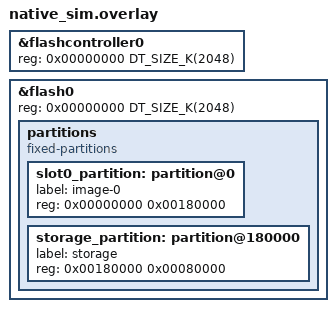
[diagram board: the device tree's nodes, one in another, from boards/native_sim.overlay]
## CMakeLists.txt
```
# SPDX-License-Identifier: GPL-3.0-or-later
#
# Method 5 (PAIRING_CA_ANCHOR_PLUS_PASSKEY) pairing gate conformance on native_sim (T-20).
#
# Drives pairing.c (CA_ANCHOR_PLUS_PASSKEY path) + ca.c + storage.c against a
# simulated LittleFS partition.  Suite setup provisions slot 0 as a CA (the
# trust anchor) and generates a test client cert signed by it.
#
# Build:
#   ZEPHYR_TOOLCHAIN_VARIANT=host \
#     west build -p -b native_sim firmware/tests/pairing_ca_anchor_passkey --no-sysbuild
#   west build -t run

cmake_minimum_required(VERSION 3.20.0)

find_package(Zephyr REQUIRED HINTS $ENV{ZEPHYR_BASE})
project(pairing_ca_anchor_passkey_tests LANGUAGES C)

set(FW ${CMAKE_CURRENT_SOURCE_DIR}/../..)

target_sources(app PRIVATE
    src/main.c
    src/session_stub.c
    src/gesture_stub.c
    src/led_stub.c
    ${FW}/src/clients/pairing.c
    ${FW}/src/clients/client_bond.c
    ${FW}/src/ca/ca.c
    ${FW}/src/ca/der_write.c
    ${FW}/src/ca/certparse_wolfssl.c
    ${FW}/src/ca/certgen_wolfssl.c
    ${FW}/src/crypto/crypto_wolfssl.c
    ${FW}/src/crypto/wc_rand.c
    ${FW}/src/crypto/zeroize.c
    ${FW}/src/storage/storage.c
    ${FW}/src/storage/volume_marker.c
    ${FW}/src/crypto/device_id.c
    ${FW}/../common/cbor/cantil_cbor.c
)

target_include_directories(app PRIVATE
    ${FW}/src
    ${FW}/include
    ${FW}/../common/cbor
    ${FW}/tests/common
)

zephyr_include_directories(${FW}/include)

# Carries WOLFSSL_USER_SETTINGS / WOLFSSL_ZEPHYR defines.
target_link_libraries(app PRIVATE wolfSSL)
```

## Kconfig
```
# SPDX-License-Identifier: GPL-3.0-or-later

mainmenu "pairing_ca_anchor_passkey ztest"

config CANTIL_MAX_KEY_SLOTS
	int "Maximum number of key slots"
	default 8
	range 1 64

config CANTIL_MAX_CLIENT_BONDS
	int "Maximum number of host-client bonds"
	default 2
	range 1 16

config CANTIL_MAX_PEER_BONDS
	int "Maximum number of peer-device bonds"
	default 2
	range 1 8

config CANTIL_CRL_VALIDITY_SEC
	int "CRL nextUpdate window (seconds)"
	default 86400

config CANTIL_REVOKE_REQUIRE_NOW_UNIX
	bool "Require host-supplied revocation timestamp"
	default n

# Pairing method symbols — flat booleans (no choice wrapper in test context).
config PAIRING_PROMISCUOUS
	bool "Method 0 — Promiscuous"
	default n

config PAIRING_TOFU
	bool "Method 1 — Silent TOFU"
	default n

config PAIRING_TAP_CONFIRM
	bool "Method 2 — Tap-confirmed bond"
	default n

config PAIRING_PASSKEY
	bool "Method 3 — Passkey + tap-confirmed bond"
	default n

config PAIRING_CA_ANCHOR
	bool "Method 4 — CA-anchored client cert"
	default n

config PAIRING_CA_ANCHOR_PLUS_PASSKEY
	bool "Method 5 — CA-anchored + passkey"
	default n

config CANTIL_CA_ANCHOR_SLOT
	int "CA slot to use as trust anchor for Method 4/5"
	default 0
	depends on PAIRING_CA_ANCHOR || PAIRING_CA_ANCHOR_PLUS_PASSKEY

config CANTIL_PAIR_TIMEOUT_SEC
	int "Pairing prompt timeout (seconds)"
	default 30

config CANTIL_PASSKEY_TIMEOUT_SEC
	int "Passkey entry timeout (seconds)"
	default 60
	depends on PAIRING_PASSKEY || PAIRING_CA_ANCHOR_PLUS_PASSKEY

config CANTIL_PASSKEY_BLINK_PAUSE_MS
	int "Inter-digit pause during passkey LED blink (milliseconds)"
	default 0
	depends on PAIRING_PASSKEY || PAIRING_CA_ANCHOR_PLUS_PASSKEY

source "Kconfig.zephyr"
```

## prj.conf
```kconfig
# ztest framework
CONFIG_ZTEST=y

# Pairing method under test.
CONFIG_PAIRING_CA_ANCHOR_PLUS_PASSKEY=y
CONFIG_CANTIL_CA_ANCHOR_SLOT=0
CONFIG_CANTIL_PAIR_TIMEOUT_SEC=30
CONFIG_CANTIL_PASSKEY_TIMEOUT_SEC=60
CONFIG_CANTIL_PASSKEY_BLINK_PAUSE_MS=0

CONFIG_CANTIL_MAX_CLIENT_BONDS=2
CONFIG_CANTIL_MAX_PEER_BONDS=2

# Entropy — native_sim has zephyr,native-posix-rng.
CONFIG_ENTROPY_GENERATOR=y
CONFIG_TEST_RANDOM_GENERATOR=y

# LittleFS on the sim flash partition.
CONFIG_FLASH=y
CONFIG_FLASH_MAP=y
CONFIG_FILE_SYSTEM=y
CONFIG_FILE_SYSTEM_LITTLEFS=y
CONFIG_FS_LITTLEFS_FMP_DEV=y
CONFIG_FILE_SYSTEM_MKFS=y

# wolfCrypt — full CA path (ECDSA P-256, AES-256-GCM, HKDF-SHA256) plus the
# X.509 writer and reader. Which primitives compile is decided by the settings
# header, not by Kconfig — see cantil_wolfssl_user_settings.h.
CONFIG_WOLFSSL=y
CONFIG_WOLFSSL_BUILTIN=y
CONFIG_WOLFSSL_SETTINGS_FILE="cantil_wolfssl_user_settings.h"

# Device-id source for the FICR-derived storage key.
CONFIG_HWINFO=y

CONFIG_MAIN_STACK_SIZE=16384
CONFIG_HEAP_MEM_POOL_SIZE=32768

# crc32_ieee — storage.c volume identity marker
CONFIG_CRC=y
```

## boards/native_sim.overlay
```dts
/* Same flash layout as other pairing tests — 512 KB storage partition. */

&flashcontroller0 {
	reg = <0x00000000 DT_SIZE_K(2048)>;
};

&flash0 {
	reg = <0x00000000 DT_SIZE_K(2048)>;
	partitions {
		compatible = "fixed-partitions";
		#address-cells = <1>;
		#size-cells = <1>;

		/delete-node/ partition@0;
		/delete-node/ partition@c000;
		/delete-node/ partition@75000;
		/delete-node/ partition@de000;
		/delete-node/ partition@fc000;

		slot0_partition: partition@0 {
			label = "image-0";
			reg = <0x00000000 0x00180000>;
		};
		storage_partition: partition@180000 {
			label = "storage";
			reg = <0x00180000 0x00080000>;
		};
	};
};
```

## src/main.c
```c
/* SPDX-License-Identifier: GPL-3.0-or-later */
/* See LICENSE at the repo root. */

/*
 * Method 5 (PAIRING_CA_ANCHOR_PLUS_PASSKEY) pairing gate conformance on
 * native_sim (T-20).
 *
 * Drives pairing.c + ca.c + storage.c against a simulated flash partition.
 * Suite setup provisions slot 0 as a CA (the trust anchor) and generates a
 * test client cert signed by it.  Per-test setup resets all stub state.
 *
 * Method 5 = cert chain validation (Method 4) + passkey + tap-confirm (Method 3).
 * A known (previously-bonded) client skips both gates.
 *
 * Coverage:
 *   1. Valid cert + correct passkey + gesture OK → bonded + PSK stored.
 *   2. No client cert in msg3 → -EACCES (cert gate rejects before passkey).
 *   3. Cert from wrong CA (self-signed) → -EACCES (cert gate).
 *   4. Valid cert + wrong passkey → -EACCES + ERR_AUTH, not bonded.
 *   5. Valid cert + transport timeout → -EACCES, not bonded.
 *   6. Valid cert + correct passkey + gesture denied → -EACCES, not bonded.
 *   7. Already-bonded client (known) → allowed with no cert or passkey.
 *   8. Valid cert + cap full → -EACCES without passkey prompt.
 */

#include <zephyr/kernel.h>
#include <zephyr/ztest.h>
#include <zephyr/fs/fs.h>
#include <string.h>
#include <errno.h>

#include "ca/ca.h"
#include "test_pki.h"
#include "crypto/crypto.h"
#include "storage/storage.h"
#include "clients/pairing.h"
#include "clients/client_bond.h"
#include "gesture/gesture.h"
#include "session/session.h"
#include "protocol/protocol.h"

/* Declared in session_stub.c */
cantil_session_t *m5_test_session(void);
void m5_test_set_client_certs(const uint8_t *const ders[], const size_t lens[], size_t count);
void m5_test_clear_client_certs(void);
void m5_test_set_reply_digits(uint32_t digits);
void m5_test_lock_digits(uint32_t digits);
void m5_test_set_reply_timeout(void);
uint32_t m5_test_last_response_err(void);
void m5_test_reset(void);

/* Declared in gesture_stub.c */
void m5_test_set_gesture_result(cantil_confirm_result_t r);

/* ── Test-owned cert DER buffers (populated once in suite_setup) ─────────── */

static uint8_t g_anchor_cert_der[1024];
static size_t g_anchor_cert_len;

static uint8_t g_valid_cert_der[1024]; /* client cert signed by slot 0 */
static size_t g_valid_cert_len;

static uint8_t g_self_signed_cert_der[1024]; /* cert with unknown CA */
static size_t g_self_signed_cert_len;

/* ── Helpers ─────────────────────────────────────────────────────────────── */

static void wipe_dir(const char *path)
{
	struct fs_dir_t dir;
	struct fs_dirent ent;
	char child[128];

	fs_dir_t_init(&dir);
	if (fs_opendir(&dir, path) != 0) {
		return;
	}
	while (fs_readdir(&dir, &ent) == 0 && ent.name[0] != '\0') {
		snprintf(child, sizeof(child), "%s/%s", path, ent.name);
		if (ent.type == FS_DIR_ENTRY_DIR) {
			wipe_dir(child);
		}
		fs_unlink(child);
	}
	fs_closedir(&dir);
	fs_unlink(path);
}

static size_t build_ca_x509_blob(uint8_t *out, size_t cap)
{
	size_t off = 0;
	const char *cn = "Cantil Test CA";
	const char *o = "Cantil";

	zassert_true(cap >= 64, "blob buffer too small");
	out[off++] = 0x01;
	out[off++] = 0x68; /* validity_days = 360 */
	out[off++] = 1;    /* is_ca */
	out[off++] = 0;    /* path_len = 0 */
	out[off++] = 0x00;
	out[off++] = 0x86; /* KU: digSig|keyCertSign|cRLSign */

	out[off++] = (uint8_t)strlen(cn);
	memcpy(&out[off], cn, strlen(cn));
	off += strlen(cn);
	out[off++] = (uint8_t)strlen(o);
	memcpy(&out[off], o, strlen(o));
	off += strlen(o);
	out[off++] = 0; /* ou */
	out[off++] = 0; /* c  */
	out[off++] = 0; /* st */
	out[off++] = 0; /* l  */
	return off;
}

/* A fresh client CSR (CN=TestClient), minted via the wolfCrypt writer. */
static int build_client_csr(uint8_t *csr_der, size_t *csr_len)
{
	return test_pki_csr_cn("TestClient", csr_der, csr_len, NULL);
}

/* A self-signed leaf under an unrelated key (CN=Unknown) — a cert that does
 * NOT chain to slot 0, which the trust-tier tests expect to be rejected. */
static int build_self_signed_cert(uint8_t *cert_der, size_t *cert_len)
{
	certgen_dn_t dn = test_pki_dn_cn("Unknown");

	return test_pki_self_signed(&dn, false, cert_der, cert_len, NULL);
}

/* ── Passkey hook ────────────────────────────────────────────────────────── */

void pairing_test_passkey_hook(uint32_t passkey)
{
	m5_test_set_reply_digits(passkey);
}

/* ── Suite setup ─────────────────────────────────────────────────────────── */

static void *suite_setup(void)
{
	zassert_ok(storage_init(), "storage_init failed");

	/*
	 * A fresh native_sim volume has no identity marker, and minting is now
	 * refused on an unmarked, empty volume — that combination is what a
	 * misdeclared partition looks like. Mark it, which is exactly what the
	 * factory image does to real hardware before anything is provisioned.
	 */
	(void)storage_volume_marker_write();

	wipe_dir("/lfs/keys/0");
	zassert_ok(ca_provision(0), "ca_provision failed");

	uint8_t blob[64];
	size_t blob_len = build_ca_x509_blob(blob, sizeof(blob));

	zassert_ok(ca_push_key_x509(0, blob, blob_len), "ca_push_key_x509 failed");
	zassert_true(ca_ready(), "slot 0 not ready after push");

	g_anchor_cert_len = sizeof(g_anchor_cert_der);
	zassert_ok(storage_slot_cert_read(0, g_anchor_cert_der, &g_anchor_cert_len),
		   "could not read slot 0 cert after push");

	/* Sign a test client CSR with slot 0 → g_valid_cert_der. */
	uint8_t csr_buf[512];
	size_t csr_len = sizeof(csr_buf);

	zassert_ok(build_client_csr(csr_buf, &csr_len), "client CSR build failed");

	g_valid_cert_len = sizeof(g_valid_cert_der);
	zassert_ok(ca_sign_csr_slot(0, csr_buf, csr_len, g_valid_cert_der, &g_valid_cert_len),
		   "CA sign CSR failed");

	/* Build a self-signed cert not anchored in slot 0 → g_self_signed_cert_der. */
	g_self_signed_cert_len = sizeof(g_self_signed_cert_der);
	zassert_ok(build_self_signed_cert(g_self_signed_cert_der, &g_self_signed_cert_len),
		   "self-signed cert build failed");

	return NULL;
}

static void before(void *unused)
{
	ARG_UNUSED(unused);
	wipe_dir("/lfs/clients");
	m5_test_reset();
	m5_test_set_gesture_result(CANTIL_CONFIRM_OK);
}

ZTEST_SUITE(pairing_ca_anchor_passkey, NULL, suite_setup, before, NULL, NULL);

static const uint8_t PUB_A[32] = {0xAA, 0x01, 0x02, 0x03, 0, 0, 0, 0, 0, 0, 0, 0, 0, 0, 0, 0,
				  0,    0,    0,    0,    0, 0, 0, 0, 0, 0, 0, 0, 0, 0, 0, 0};
static const uint8_t PUB_B[32] = {0xBB, 0x01, 0x02, 0x03, 0, 0, 0, 0, 0, 0, 0, 0, 0, 0, 0, 0,
				  0,    0,    0,    0,    0, 0, 0, 0, 0, 0, 0, 0, 0, 0, 0, 0};
static const uint8_t PUB_C[32] = {0xCC, 0x01, 0x02, 0x03, 0, 0, 0, 0, 0, 0, 0, 0, 0, 0, 0, 0,
				  0,    0,    0,    0,    0, 0, 0, 0, 0, 0, 0, 0, 0, 0, 0, 0};

/* ── Test 1: valid cert + correct passkey + gesture OK → bonded + PSK ───── */

ZTEST(pairing_ca_anchor_passkey, test_valid_cert_passkey_bonded)
{
	const uint8_t *ders[1] = {g_valid_cert_der};
	size_t lens[1] = {g_valid_cert_len};

	m5_test_set_client_certs(ders, lens, 1);

	cantil_session_t *s = m5_test_session();

	zassert_ok(pairing_check_and_bond(PUB_A, s),
		   "Method 5: valid cert + passkey should be allowed");

	zassert_equal(client_bond_exists(PUB_A), 1, "bond not stored after Method 5 success");

	/* PSK file must exist and be non-empty. */
	uint8_t id[4] = {0xAA, 0x01, 0x02, 0x03};
	uint8_t psk_enc[64];
	size_t psk_enc_len = sizeof(psk_enc);

	zassert_ok(storage_client_bond_psk_read(id, psk_enc, &psk_enc_len),
		   "PSK not stored after Method 5");
	zassert_true(psk_enc_len > 0, "PSK blob is empty");

	zassert_equal(m5_test_last_response_err(), (uint32_t)ERR_OK,
		      "device sent non-OK response on success");
}

/* ── Test 2: no cert in msg3 → rejected before passkey ──────────────────── */

ZTEST(pairing_ca_anchor_passkey, test_no_cert_rejected)
{
	/* No certs injected — stub returns cert_count == 0. */
	m5_test_set_reply_timeout(); /* recv would error if called */

	cantil_session_t *s = m5_test_session();
	int rc = pairing_check_and_bond(PUB_A, s);

	zassert_equal(rc, -EACCES, "Method 5: no cert should be rejected, got %d", rc);
	zassert_equal(client_bond_exists(PUB_A), 0, "bonded despite missing cert");
}

/* ── Test 3: self-signed cert (wrong CA) → rejected before passkey ───────── */

ZTEST(pairing_ca_anchor_passkey, test_wrong_ca_rejected)
{
	const uint8_t *ders[1] = {g_self_signed_cert_der};
	size_t lens[1] = {g_self_signed_cert_len};

	m5_test_set_client_certs(ders, lens, 1);
	m5_test_set_reply_timeout(); /* recv would error if called */

	cantil_session_t *s = m5_test_session();
	int rc = pairing_check_and_bond(PUB_A, s);

	zassert_equal(rc, -EACCES, "Method 5: cert from wrong CA should be rejected, got %d", rc);
	zassert_equal(client_bond_exists(PUB_A), 0, "bonded despite invalid cert");
}

/* ── Test 4: valid cert + wrong passkey → -EACCES + ERR_AUTH ────────────── */

ZTEST(pairing_ca_anchor_passkey, test_wrong_passkey_rejected)
{
	const uint8_t *ders[1] = {g_valid_cert_der};
	size_t lens[1] = {g_valid_cert_len};

	m5_test_set_client_certs(ders, lens, 1);
	/* Lock stub to 0 — generate_passkey() never returns 0, so always a mismatch. */
	m5_test_lock_digits(0U);

	cantil_session_t *s = m5_test_session();
	int rc = pairing_check_and_bond(PUB_A, s);

	zassert_equal(rc, -EACCES, "Method 5: wrong passkey should reject, got %d", rc);
	zassert_equal(client_bond_exists(PUB_A), 0, "bonded despite wrong passkey");
	zassert_equal(m5_test_last_response_err(), (uint32_t)ERR_AUTH,
		      "expected ERR_AUTH response, got %u", m5_test_last_response_err());
}

/* ── Test 5: valid cert + passkey recv timeout → -EACCES ─────────────────── */

ZTEST(pairing_ca_anchor_passkey, test_timeout_rejected)
{
	const uint8_t *ders[1] = {g_valid_cert_der};
	size_t lens[1] = {g_valid_cert_len};

	m5_test_set_client_certs(ders, lens, 1);
	m5_test_set_reply_timeout();

	cantil_session_t *s = m5_test_session();
	int rc = pairing_check_and_bond(PUB_A, s);

	zassert_equal(rc, -EACCES, "Method 5: passkey timeout should reject, got %d", rc);
	zassert_equal(client_bond_exists(PUB_A), 0, "bonded despite timeout");
}

/* ── Test 6: valid cert + correct passkey + gesture denied → -EACCES ──────── */

ZTEST(pairing_ca_anchor_passkey, test_gesture_denied_rejected)
{
	const uint8_t *ders[1] = {g_valid_cert_der};
	size_t lens[1] = {g_valid_cert_len};

	m5_test_set_client_certs(ders, lens, 1);
	m5_test_set_gesture_result(CANTIL_CONFIRM_DENIED);

	cantil_session_t *s = m5_test_session();
	int rc = pairing_check_and_bond(PUB_A, s);

	zassert_equal(rc, -EACCES, "Method 5: denied gesture should reject, got %d", rc);
	zassert_equal(client_bond_exists(PUB_A), 0, "bonded despite denied gesture");
}

/* ── Test 7: already-bonded client → allowed with no cert or passkey ─────── */

ZTEST(pairing_ca_anchor_passkey, test_known_client_allowed)
{
	/* Pre-establish a bond for PUB_A. */
	zassert_ok(client_bond_add(PUB_A, CLIENT_KIND_HOST, 0), "setup bond");

	/* No cert injected, recv would timeout if called. */
	m5_test_set_reply_timeout();

	cantil_session_t *s = m5_test_session();

	zassert_ok(pairing_check_and_bond(PUB_A, s), "Method 5: known client should be allowed");

	uint32_t hosts = 0, peers = 0;

	zassert_ok(client_bond_count(&hosts, &peers), "count failed");
	zassert_equal(hosts, 1, "expected 1 bond, got %u", hosts);
}

/* ── Test 8: valid cert + cap full → -EACCES without passkey prompt ─────── */

ZTEST(pairing_ca_anchor_passkey, test_cap_full_rejected)
{
	/* Fill the cap (max 2 per prj.conf). */
	zassert_ok(client_bond_add(PUB_A, CLIENT_KIND_HOST, 0), "bond A");
	zassert_ok(client_bond_add(PUB_B, CLIENT_KIND_HOST, 0), "bond B");

	const uint8_t *ders[1] = {g_valid_cert_der};
	size_t lens[1] = {g_valid_cert_len};

	m5_test_set_client_certs(ders, lens, 1);
	m5_test_set_reply_timeout(); /* recv must not be called */

	cantil_session_t *s = m5_test_session();
	int rc = pairing_check_and_bond(PUB_C, s);

	zassert_equal(rc, -EACCES, "Method 5: cap full should reject, got %d", rc);
	zassert_equal(client_bond_exists(PUB_C), 0, "bonded despite cap full");
}
```

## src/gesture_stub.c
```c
/* SPDX-License-Identifier: GPL-3.0-or-later */
/* See LICENSE at the repo root. */

#include "gesture/gesture.h"

static cantil_confirm_result_t stub_result = CANTIL_CONFIRM_OK;

void m5_test_set_gesture_result(cantil_confirm_result_t r)
{
	stub_result = r;
}

int gesture_request_pair_confirm(cantil_confirm_cb_t cb, void *user_data)
{
	cb(stub_result, user_data);
	return 0;
}
```

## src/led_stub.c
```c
/* SPDX-License-Identifier: GPL-3.0-or-later */
/* See LICENSE at the repo root. */

#include <zephyr/kernel.h>
#include "led/led.h"

int led_init(void)
{
	return 0;
}

void led_set_idle(led_pattern_t pattern)
{
	ARG_UNUSED(pattern);
}
void led_play_oneshot(led_pattern_t pattern)
{
	ARG_UNUSED(pattern);
}
void led_set_pattern(led_pattern_t pattern)
{
	ARG_UNUSED(pattern);
}

void led_blink_digit(uint8_t digit)
{
	ARG_UNUSED(digit);
}

void led_diag_flash(uint8_t color, uint32_t ms)
{
	ARG_UNUSED(color);
	ARG_UNUSED(ms);
}
```

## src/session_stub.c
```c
/* SPDX-License-Identifier: GPL-3.0-or-later */
/* See LICENSE at the repo root. */

/*
 * Session stub for the pairing_ca_anchor_passkey ztest suite (T-20).
 *
 * pairing.c (PAIRING_CA_ANCHOR_PLUS_PASSKEY) calls:
 *   session_get_client_cert_count() — how many client certs the peer sent
 *   session_get_client_cert()       — borrow the Nth cert DER
 *   session_recv()                  — receive CMD_PAIRING_PASSKEY_REPLY
 *   session_send()                  — send the pairing response
 *   session_get_local_pubkey()      — device static pubkey for PSK derivation
 *
 * Test controls:
 *   m5_test_session()                — return the stub cantil_session_t *
 *   m5_test_set_client_certs()       — inject client cert chain
 *   m5_test_clear_client_certs()     — reset to "no cert" (cert_count == 0)
 *   m5_test_set_reply_digits(d)      — session_recv returns CBOR{cmd=0x73, data=d}
 *   m5_test_lock_digits(d)           — same, but ignores hook overrides
 *   m5_test_set_reply_timeout()      — session_recv returns -ETIMEDOUT
 *   m5_test_last_response_err()      — last err value from session_send
 *   m5_test_reset()                  — clear all passkey/recv state
 */

#include <zephyr/kernel.h>
#include <string.h>
#include <errno.h>

#include "session/session.h"
#include "cantil_cbor.h"
#include "protocol/protocol.h"

#define MAX_TEST_CERTS 4

struct cantil_session {
	bool established;
	/* Injected client cert chain (borrowed pointers). */
	const uint8_t *cert_ders[MAX_TEST_CERTS];
	size_t cert_lens[MAX_TEST_CERTS];
	size_t cert_count;
};

static struct cantil_session stub_session = {.established = true};

cantil_session_t *m5_test_session(void)
{
	return &stub_session;
}

/* ── Cert injection controls ─────────────────────────────────────────────── */

void m5_test_set_client_certs(const uint8_t *const ders[], const size_t lens[], size_t count)
{
	stub_session.cert_count = (count > MAX_TEST_CERTS) ? MAX_TEST_CERTS : count;
	for (size_t i = 0; i < stub_session.cert_count; i++) {
		stub_session.cert_ders[i] = ders[i];
		stub_session.cert_lens[i] = lens[i];
	}
}

void m5_test_clear_client_certs(void)
{
	stub_session.cert_count = 0;
}

/* ── Passkey reply controls ──────────────────────────────────────────────── */

static uint32_t stub_digits = 0;
static bool stub_digits_locked = false;
static bool stub_timeout = false;
static uint32_t stub_last_err = UINT32_MAX;

void m5_test_set_reply_digits(uint32_t digits)
{
	if (!stub_digits_locked) {
		stub_digits = digits;
	}
}

void m5_test_lock_digits(uint32_t digits)
{
	stub_digits = digits;
	stub_digits_locked = true;
}

void m5_test_set_reply_timeout(void)
{
	stub_timeout = true;
}

uint32_t m5_test_last_response_err(void)
{
	return stub_last_err;
}

void m5_test_reset(void)
{
	stub_session.cert_count = 0;
	stub_digits = 0;
	stub_digits_locked = false;
	stub_timeout = false;
	stub_last_err = UINT32_MAX;
}

/* ── session API stubs ───────────────────────────────────────────────────── */

size_t session_get_client_cert_count(const cantil_session_t *s)
{
	return s ? s->cert_count : 0;
}

int session_get_client_cert(const cantil_session_t *s, size_t idx, const uint8_t **der, size_t *len)
{
	if (!s || !der || !len) {
		return -EINVAL;
	}
	if (idx >= s->cert_count) {
		return -ENOENT;
	}
	*der = s->cert_ders[idx];
	*len = s->cert_lens[idx];
	return 0;
}

int session_recv(cantil_session_t *session, uint8_t *buf, size_t max_len, size_t *received)
{
	ARG_UNUSED(session);

	if (stub_timeout) {
		return -ETIMEDOUT;
	}

	uint8_t digit_cbor[9];
	size_t digit_cbor_len = 0;

	if (cantil_cbor_emit_uint(digit_cbor, sizeof(digit_cbor), &digit_cbor_len, stub_digits) !=
	    0) {
		return -EIO;
	}

	int n = cantil_cbor_encode_request(buf, max_len, CMD_PAIRING_PASSKEY_REPLY, 1, digit_cbor,
					   digit_cbor_len);
	if (n < 0) {
		return -ENOMEM;
	}
	*received = (size_t)n;
	return 0;
}

int session_send(cantil_session_t *session, const uint8_t *buf, size_t len)
{
	ARG_UNUSED(session);

	uint32_t seq = 0, err = UINT32_MAX;
	const uint8_t *data = NULL;
	size_t data_len = 0;

	if (cantil_cbor_decode_response(buf, len, &seq, &err, &data, &data_len) == 0) {
		stub_last_err = err;
	}
	return 0;
}

int session_get_local_pubkey(cantil_session_t *session, uint8_t pubkey[32])
{
	ARG_UNUSED(session);
	memset(pubkey, 0x55, 32);
	return 0;
}

int session_open(cantil_transport_t *t, const uint8_t *pub, cantil_session_t **out)
{
	ARG_UNUSED(t);
	ARG_UNUSED(pub);
	ARG_UNUSED(out);
	return -ENOSYS;
}

void session_close(cantil_session_t *s)
{
	ARG_UNUSED(s);
}

int session_get_remote_pubkey(cantil_session_t *session, uint8_t pubkey[32])
{
	ARG_UNUSED(session);
	ARG_UNUSED(pubkey);
	return -ENOSYS;
}
```
